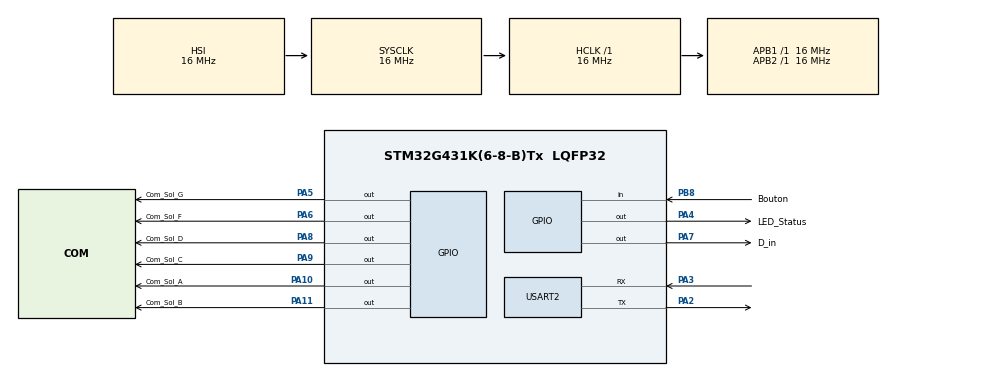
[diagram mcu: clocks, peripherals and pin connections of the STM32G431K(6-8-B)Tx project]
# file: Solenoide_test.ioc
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Mcu.Family=STM32G4
Mcu.Name=STM32G431K(6-8-B)Tx
Mcu.Package=LQFP32
NVIC.PriorityGroup=NVIC_PRIORITYGROUP_4
PA10.GPIO_Label=Com_Sol_A
PA10.Signal=GPIO_Output
PA11.GPIO_Label=Com_Sol_B
PA11.Signal=GPIO_Output
PA13.Signal=SYS_JTMS-SWDIO
PA14.Signal=SYS_JTCK-SWCLK
PA2.Mode=Asynchronous
PA2.Signal=USART2_TX
PA3.Mode=Asynchronous
PA3.Signal=USART2_RX
PA4.GPIO_Label=LED_Status
PA4.Signal=GPIO_Output
PA5.GPIO_Label=Com_Sol_G
PA5.Signal=GPIO_Output
PA6.GPIO_Label=Com_Sol_F
PA6.Signal=GPIO_Output
PA7.GPIO_Label=D_in
PA7.Signal=GPIO_Output
PA8.GPIO_Label=Com_Sol_D
PA8.Signal=GPIO_Output
PA9.GPIO_Label=Com_Sol_C
PA9.Signal=GPIO_Output
PB8-BOOT0.GPIO_Label=Bouton
PB8-BOOT0.Signal=GPIO_Input
ProjectManager.HeapSize=0x200
ProjectManager.StackSize=0x400
ProjectManager.TargetToolchain=STM32CubeIDE
RCC.AHBFreq_Value=16000000
RCC.APB1Freq_Value=16000000
RCC.APB1TimFreq_Value=16000000
RCC.APB2Freq_Value=16000000
RCC.APB2TimFreq_Value=16000000
RCC.CortexFreq_Value=16000000
RCC.EXTERNAL_CLOCK_VALUE=12288000
RCC.HCLKFreq_Value=16000000
RCC.HSE_VALUE=8000000
RCC.HSI48_VALUE=48000000
RCC.HSI_VALUE=16000000
RCC.LSE_VALUE=32768
RCC.SYSCLKFreq_VALUE=16000000
RCC.USBFreq_Value=64000000
RCC.VCOOutputFreq_Value=128000000
USART2.VirtualMode-Asynchronous=VM_ASYNC
VP_SYS_VS_DBSignals.Mode=DisableDeadBatterySignals
board=custom

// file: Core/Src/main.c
/* USER CODE BEGIN Header */
/**
  ******************************************************************************
  * @file           : main.c
  * @brief          : Main program body
  ******************************************************************************
  * @attention
  *
  * Copyright (c) 2025 STMicroelectronics.
  * All rights reserved.
  *
  * This software is licensed under terms that can be found in the LICENSE file
  * in the root directory of this software component.
  * If no LICENSE file comes with this software, it is provided AS-IS.
  *
  ******************************************************************************
  */
/* USER CODE END Header */
#include "main.h"
#include "utils.h"

UART_HandleTypeDef huart2;

void SystemClock_Config(void);
static void MX_GPIO_Init(void);
static void MX_USART2_UART_Init(void);

/* USER CODE BEGIN 0 */
int __io_putchar(int chr){
	HAL_UART_Transmit(&huart2, (uint8_t*)&chr, 1, HAL_MAX_DELAY);

	return 0;
}
/* USER CODE END 0 */

int main(void)
{

  /* MCU Configuration--------------------------------------------------------*/

  /* Reset of all peripherals, Initializes the Flash interface and the Systick. */
  HAL_Init();

  /* Configure the system clock */
  SystemClock_Config();

  /* Initialize all configured peripherals */
  MX_GPIO_Init();
  MX_USART2_UART_Init();
  /* USER CODE BEGIN 2 */
  setup();
  /* USER CODE END 2 */

  /* Infinite loop */
  while (1)
  {

    /* USER CODE BEGIN 3 */
	  loop();
  }
  /* USER CODE END 3 */
}

void SystemClock_Config(void)
{
  RCC_OscInitTypeDef RCC_OscInitStruct = {0};
  RCC_ClkInitTypeDef RCC_ClkInitStruct = {0};

  /** Configure the main internal regulator output voltage
  */
  HAL_PWREx_ControlVoltageScaling(PWR_REGULATOR_VOLTAGE_SCALE1);

  /** Initializes the RCC Oscillators according to the specified parameters
  * in the RCC_OscInitTypeDef structure.
  */
  RCC_OscInitStruct.OscillatorType = RCC_OSCILLATORTYPE_HSI;
  RCC_OscInitStruct.HSIState = RCC_HSI_ON;
  RCC_OscInitStruct.HSICalibrationValue = RCC_HSICALIBRATION_DEFAULT;
  RCC_OscInitStruct.PLL.PLLState = RCC_PLL_NONE;
  if (HAL_RCC_OscConfig(&RCC_OscInitStruct) != HAL_OK)
  {
    Error_Handler();
  }

  /** Initializes the CPU, AHB and APB buses clocks
  */
  RCC_ClkInitStruct.ClockType = RCC_CLOCKTYPE_HCLK|RCC_CLOCKTYPE_SYSCLK
                              |RCC_CLOCKTYPE_PCLK1|RCC_CLOCKTYPE_PCLK2;
  RCC_ClkInitStruct.SYSCLKSource = RCC_SYSCLKSOURCE_HSI;
  RCC_ClkInitStruct.AHBCLKDivider = RCC_SYSCLK_DIV1;
  RCC_ClkInitStruct.APB1CLKDivider = RCC_HCLK_DIV1;
  RCC_ClkInitStruct.APB2CLKDivider = RCC_HCLK_DIV1;

  if (HAL_RCC_ClockConfig(&RCC_ClkInitStruct, FLASH_LATENCY_0) != HAL_OK)
  {
    Error_Handler();
  }
}

static void MX_USART2_UART_Init(void)
{

  huart2.Instance = USART2;
  huart2.Init.BaudRate = 115200;
  huart2.Init.WordLength = UART_WORDLENGTH_8B;
  huart2.Init.StopBits = UART_STOPBITS_1;
  huart2.Init.Parity = UART_PARITY_NONE;
  huart2.Init.Mode = UART_MODE_TX_RX;
  huart2.Init.HwFlowCtl = UART_HWCONTROL_NONE;
  huart2.Init.OverSampling = UART_OVERSAMPLING_16;
  huart2.Init.OneBitSampling = UART_ONE_BIT_SAMPLE_DISABLE;
  huart2.Init.ClockPrescaler = UART_PRESCALER_DIV1;
  huart2.AdvancedInit.AdvFeatureInit = UART_ADVFEATURE_NO_INIT;
  if (HAL_UART_Init(&huart2) != HAL_OK)
  {
    Error_Handler();
  }
  if (HAL_UARTEx_SetTxFifoThreshold(&huart2, UART_TXFIFO_THRESHOLD_1_8) != HAL_OK)
  {
    Error_Handler();
  }
  if (HAL_UARTEx_SetRxFifoThreshold(&huart2, UART_RXFIFO_THRESHOLD_1_8) != HAL_OK)
  {
    Error_Handler();
  }
  if (HAL_UARTEx_DisableFifoMode(&huart2) != HAL_OK)
  {
    Error_Handler();
  }

}

static void MX_GPIO_Init(void)
{
  GPIO_InitTypeDef GPIO_InitStruct = {0};

  /* GPIO Ports Clock Enable */
  __HAL_RCC_GPIOA_CLK_ENABLE();
  __HAL_RCC_GPIOB_CLK_ENABLE();

  /*Configure GPIO pin Output Level */
  HAL_GPIO_WritePin(GPIOA, LED_Status_Pin|Com_Sol_G_Pin|Com_Sol_F_Pin|D_in_Pin
                          |Com_Sol_D_Pin|Com_Sol_C_Pin|Com_Sol_A_Pin|Com_Sol_B_Pin, GPIO_PIN_RESET);

  /*Configure GPIO pins : LED_Status_Pin Com_Sol_G_Pin Com_Sol_F_Pin D_in_Pin
                           Com_Sol_D_Pin Com_Sol_C_Pin Com_Sol_A_Pin Com_Sol_B_Pin */
  GPIO_InitStruct.Pin = LED_Status_Pin|Com_Sol_G_Pin|Com_Sol_F_Pin|D_in_Pin
                          |Com_Sol_D_Pin|Com_Sol_C_Pin|Com_Sol_A_Pin|Com_Sol_B_Pin;
  GPIO_InitStruct.Mode = GPIO_MODE_OUTPUT_PP;
  GPIO_InitStruct.Pull = GPIO_NOPULL;
  GPIO_InitStruct.Speed = GPIO_SPEED_FREQ_LOW;
  HAL_GPIO_Init(GPIOA, &GPIO_InitStruct);

  /*Configure GPIO pin : Bouton_Pin */
  GPIO_InitStruct.Pin = Bouton_Pin;
  GPIO_InitStruct.Mode = GPIO_MODE_INPUT;
  GPIO_InitStruct.Pull = GPIO_NOPULL;
  HAL_GPIO_Init(Bouton_GPIO_Port, &GPIO_InitStruct);

}

void Error_Handler(void)
{
  __disable_irq();
  while (1)
  {
  }
}
